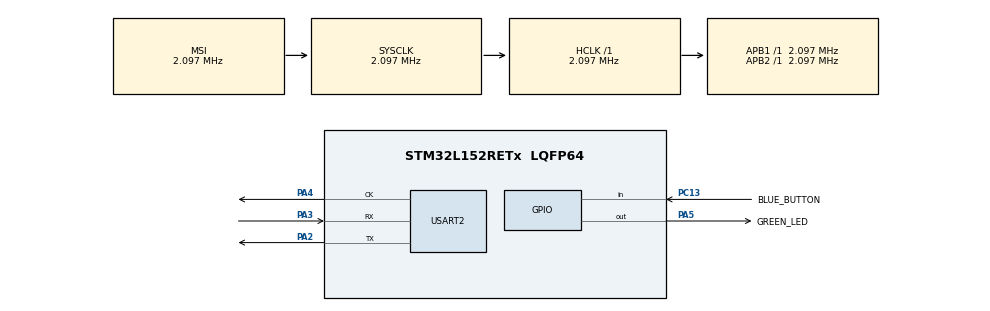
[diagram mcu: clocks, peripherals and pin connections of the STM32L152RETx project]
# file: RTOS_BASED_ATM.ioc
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FREERTOS.BinarySemaphores01=bin_sema,Dynamic,NULL
FREERTOS.Queues01=input,5,uint16_t,0,Dynamic,NULL,NULL
FREERTOS.Tasks01=rtc_task,24,128,StartDefaultTask,Default,NULL,Dynamic,NULL,NULL;menu,8,128,StartTask04,Default,NULL,Dynamic,NULL,NULL;input_processin,8,128,StartTask05,Default,NULL,Dynamic,NULL,NULL
FREERTOS.configUSE_PREEMPTION=0
Mcu.Family=STM32L1
Mcu.Name=STM32L152RETx
Mcu.Package=LQFP64
NVIC.PriorityGroup=NVIC_PRIORITYGROUP_4
NVIC.TIM6_IRQn=true\:0\:0\:false\:false\:true\:false\:false\:true
NVIC.TimeBase=TIM6_IRQn
NVIC.TimeBaseIP=TIM6
PA2.Mode=Synchronous
PA2.Signal=USART2_TX
PA3.Mode=Synchronous
PA3.Signal=USART2_RX
PA4.Mode=Synchronous
PA4.Signal=USART2_CK
PA5.GPIO_Label=GREEN_LED
PA5.Signal=GPIO_Output
PC13-WKUP2.GPIO_Label=BLUE_BUTTON
PC13-WKUP2.Signal=GPIO_Input
ProjectManager.HeapSize=0x200
ProjectManager.StackSize=0x400
ProjectManager.TargetToolchain=STM32CubeIDE
RCC.AHBFreq_Value=2097000
RCC.APB1Freq_Value=2097000
RCC.APB2Freq_Value=2097000
RCC.HSE_VALUE=24000000
RCC.HSI_VALUE=16000000
RCC.LSE_VALUE=32768
RCC.MSI_VALUE=2097000
RCC.SYSCLKFreq_VALUE=2097000
RCC.VCOOutputFreq_Value=48000000
USART2.VirtualMode=VM_SYNC
VP_FREERTOS_VS_CMSIS_V2.Mode=CMSIS_V2
VP_RTC_VS_RTC_Activate.Mode=RTC_Enabled
VP_SYS_VS_tim6.Mode=TIM6
board=custom

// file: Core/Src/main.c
/* USER CODE BEGIN Header */
/**
  ******************************************************************************
  * @file           : main.c
  * @brief          : Main program body
  ******************************************************************************
  * @attention
  *
  * <h2><center>&copy; Copyright (c) 2021 STMicroelectronics.
  * All rights reserved.</center></h2>
  *
  * This software component is licensed by ST under BSD 3-Clause license,
  * the "License"; You may not use this file except in compliance with the
  * License. You may obtain a copy of the License at:
  *                        opensource.org/licenses/BSD-3-Clause
  *
  ******************************************************************************
  */
/* USER CODE END Header */
#include "main.h"
#include "cmsis_os.h"

/* USER CODE BEGIN PD */
#define DWT_CTRL		(*(volatile uint32_t*)0xE0001000)
/* USER CODE END PD */

RTC_HandleTypeDef hrtc;

USART_HandleTypeDef husart2;

/* Definitions for rtc_task */
osThreadId_t rtc_taskHandle;
const osThreadAttr_t rtc_task_attributes = {
  .name = "rtc_task",
  .priority = (osPriority_t) osPriorityNormal,
  .stack_size = 128 * 4
};
/* Definitions for menu */
osThreadId_t menuHandle;
const osThreadAttr_t menu_attributes = {
  .name = "menu",
  .priority = (osPriority_t) osPriorityLow,
  .stack_size = 128 * 4
};
/* Definitions for input_processin */
osThreadId_t input_processinHandle;
const osThreadAttr_t input_processin_attributes = {
  .name = "input_processin",
  .priority = (osPriority_t) osPriorityLow,
  .stack_size = 128 * 4
};
/* Definitions for input */
osMessageQueueId_t inputHandle;
const osMessageQueueAttr_t input_attributes = {
  .name = "input"
};
/* Definitions for bin_sema */
osSemaphoreId_t bin_semaHandle;
const osSemaphoreAttr_t bin_sema_attributes = {
  .name = "bin_sema"
};

void SystemClock_Config(void);
static void MX_GPIO_Init(void);
static void MX_RTC_Init(void);
static void MX_USART2_Init(void);
void StartDefaultTask(void *argument);
void StartTask04(void *argument);
void StartTask05(void *argument);

int main(void)
{

  /* MCU Configuration--------------------------------------------------------*/

  /* Reset of all peripherals, Initializes the Flash interface and the Systick. */
  HAL_Init();

  /* Configure the system clock */
  SystemClock_Config();

  /* Initialize all configured peripherals */
  MX_GPIO_Init();
  MX_RTC_Init();
  MX_USART2_Init();
  /* USER CODE BEGIN 2 */
  DWT_CTRL |= (1 << 0);

  SEGGER_SYSVIEW_Conf();
  SEGGER_SYSVIEW_Start();

  /* USER CODE END 2 */

  /* Init scheduler */
  osKernelInitialize();

  /* Create the semaphores(s) */
  /* creation of bin_sema */
  bin_semaHandle = osSemaphoreNew(1, 1, &bin_sema_attributes);

  /* Create the queue(s) */
  /* creation of input */
  inputHandle = osMessageQueueNew (5, sizeof(uint16_t), &input_attributes);

  /* Create the thread(s) */
  /* creation of rtc_task */
  rtc_taskHandle = osThreadNew(StartDefaultTask, NULL, &rtc_task_attributes);

  /* creation of menu */
  menuHandle = osThreadNew(StartTask04, NULL, &menu_attributes);

  /* creation of input_processin */
  input_processinHandle = osThreadNew(StartTask05, NULL, &input_processin_attributes);

  /* Start scheduler */
  osKernelStart();

  /* We should never get here as control is now taken by the scheduler */
  /* Infinite loop */
  while (1)
  {

  }
}

void SystemClock_Config(void)
{
  RCC_OscInitTypeDef RCC_OscInitStruct = {0};
  RCC_ClkInitTypeDef RCC_ClkInitStruct = {0};
  RCC_PeriphCLKInitTypeDef PeriphClkInit = {0};

  /** Configure the main internal regulator output voltage
  */
  __HAL_PWR_VOLTAGESCALING_CONFIG(PWR_REGULATOR_VOLTAGE_SCALE1);
  /** Initializes the RCC Oscillators according to the specified parameters
  * in the RCC_OscInitTypeDef structure.
  */
  RCC_OscInitStruct.OscillatorType = RCC_OSCILLATORTYPE_LSI|RCC_OSCILLATORTYPE_MSI;
  RCC_OscInitStruct.LSIState = RCC_LSI_ON;
  RCC_OscInitStruct.MSIState = RCC_MSI_ON;
  RCC_OscInitStruct.MSICalibrationValue = 0;
  RCC_OscInitStruct.MSIClockRange = RCC_MSIRANGE_5;
  RCC_OscInitStruct.PLL.PLLState = RCC_PLL_NONE;
  if (HAL_RCC_OscConfig(&RCC_OscInitStruct) != HAL_OK)
  {
    Error_Handler();
  }
  /** Initializes the CPU, AHB and APB buses clocks
  */
  RCC_ClkInitStruct.ClockType = RCC_CLOCKTYPE_HCLK|RCC_CLOCKTYPE_SYSCLK
                              |RCC_CLOCKTYPE_PCLK1|RCC_CLOCKTYPE_PCLK2;
  RCC_ClkInitStruct.SYSCLKSource = RCC_SYSCLKSOURCE_MSI;
  RCC_ClkInitStruct.AHBCLKDivider = RCC_SYSCLK_DIV1;
  RCC_ClkInitStruct.APB1CLKDivider = RCC_HCLK_DIV1;
  RCC_ClkInitStruct.APB2CLKDivider = RCC_HCLK_DIV1;

  if (HAL_RCC_ClockConfig(&RCC_ClkInitStruct, FLASH_LATENCY_0) != HAL_OK)
  {
    Error_Handler();
  }
  PeriphClkInit.PeriphClockSelection = RCC_PERIPHCLK_RTC;
  PeriphClkInit.RTCClockSelection = RCC_RTCCLKSOURCE_LSI;
  if (HAL_RCCEx_PeriphCLKConfig(&PeriphClkInit) != HAL_OK)
  {
    Error_Handler();
  }
}

static void MX_RTC_Init(void)
{

  /** Initialize RTC Only
  */
  hrtc.Instance = RTC;
  hrtc.Init.HourFormat = RTC_HOURFORMAT_24;
  hrtc.Init.AsynchPrediv = 127;
  hrtc.Init.SynchPrediv = 255;
  hrtc.Init.OutPut = RTC_OUTPUT_DISABLE;
  hrtc.Init.OutPutPolarity = RTC_OUTPUT_POLARITY_HIGH;
  hrtc.Init.OutPutType = RTC_OUTPUT_TYPE_OPENDRAIN;
  if (HAL_RTC_Init(&hrtc) != HAL_OK)
  {
    Error_Handler();
  }

}

static void MX_USART2_Init(void)
{

  husart2.Instance = USART2;
  husart2.Init.BaudRate = 115200;
  husart2.Init.WordLength = USART_WORDLENGTH_8B;
  husart2.Init.StopBits = USART_STOPBITS_1;
  husart2.Init.Parity = USART_PARITY_NONE;
  husart2.Init.Mode = USART_MODE_TX_RX;
  husart2.Init.CLKPolarity = USART_POLARITY_LOW;
  husart2.Init.CLKPhase = USART_PHASE_1EDGE;
  husart2.Init.CLKLastBit = USART_LASTBIT_DISABLE;
  if (HAL_USART_Init(&husart2) != HAL_OK)
  {
    Error_Handler();
  }

}

static void MX_GPIO_Init(void)
{
  GPIO_InitTypeDef GPIO_InitStruct = {0};

  /* GPIO Ports Clock Enable */
  __HAL_RCC_GPIOC_CLK_ENABLE();
  __HAL_RCC_GPIOA_CLK_ENABLE();

  /*Configure GPIO pin Output Level */
  HAL_GPIO_WritePin(GREEN_LED_GPIO_Port, GREEN_LED_Pin, GPIO_PIN_RESET);

  /*Configure GPIO pin : BLUE_BUTTON_Pin */
  GPIO_InitStruct.Pin = BLUE_BUTTON_Pin;
  GPIO_InitStruct.Mode = GPIO_MODE_INPUT;
  GPIO_InitStruct.Pull = GPIO_NOPULL;
  HAL_GPIO_Init(BLUE_BUTTON_GPIO_Port, &GPIO_InitStruct);

  /*Configure GPIO pin : GREEN_LED_Pin */
  GPIO_InitStruct.Pin = GREEN_LED_Pin;
  GPIO_InitStruct.Mode = GPIO_MODE_OUTPUT_PP;
  GPIO_InitStruct.Pull = GPIO_NOPULL;
  GPIO_InitStruct.Speed = GPIO_SPEED_FREQ_LOW;
  HAL_GPIO_Init(GREEN_LED_GPIO_Port, &GPIO_InitStruct);

}

void StartDefaultTask(void *argument)
{
  for(;;)
  {
    osDelay(1);
  }
}

void StartTask04(void *argument)
{
  for(;;)
  {
    osDelay(1);
  }
}

void StartTask05(void *argument)
{
  for(;;)
  {
    osDelay(1);
  }
}

 /**
  * @brief  Period elapsed callback in non blocking mode
  * @note   This function is called  when TIM6 interrupt took place, inside
  * HAL_TIM_IRQHandler(). It makes a direct call to HAL_IncTick() to increment
  * a global variable "uwTick" used as application time base.
  * @param  htim : TIM handle
  * @retval None
  */
void HAL_TIM_PeriodElapsedCallback(TIM_HandleTypeDef *htim)
{
  if (htim->Instance == TIM6) {
    HAL_IncTick();
  }
}

void Error_Handler(void)
{
  __disable_irq();
  while (1)
  {
  }
}

/************************ (C) COPYRIGHT STMicroelectronics *****END OF FILE****/
